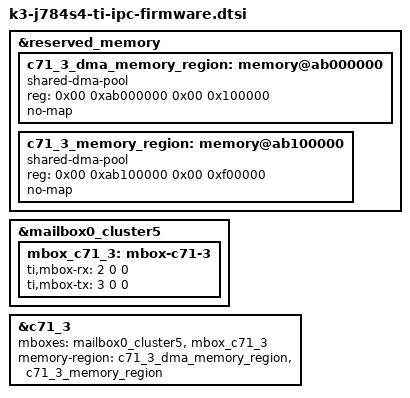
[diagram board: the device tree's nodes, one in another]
// SPDX-License-Identifier: GPL-2.0-only OR MIT
/**
 * Device Tree Source for enabling IPC using TI SDK firmware on J784S4 SoCs
 *
 * Copyright (C) 2022-2025 Texas Instruments Incorporated - https://www.ti.com/
 */

&reserved_memory {
	c71_3_dma_memory_region: memory@ab000000 {
		compatible = "shared-dma-pool";
		reg = <0x00 0xab000000 0x00 0x100000>;
		no-map;
	};

	c71_3_memory_region: memory@ab100000 {
		compatible = "shared-dma-pool";
		reg = <0x00 0xab100000 0x00 0xf00000>;
		no-map;
	};
};

&mailbox0_cluster5 {

	mbox_c71_3: mbox-c71-3 {
		ti,mbox-rx = <2 0 0>;
		ti,mbox-tx = <3 0 0>;
	};
};

&c71_3 {
	mboxes = <&mailbox0_cluster5 &mbox_c71_3>;
	memory-region = <&c71_3_dma_memory_region>,
			<&c71_3_memory_region>;
	status = "okay";
};
